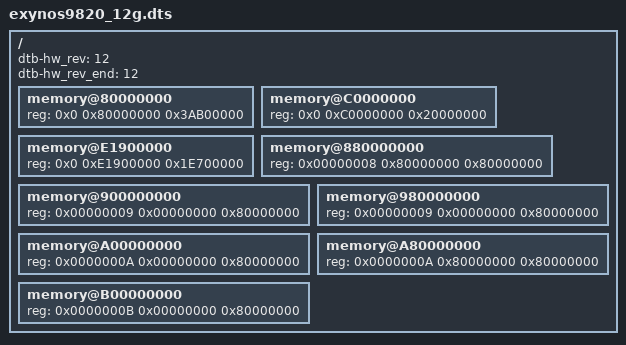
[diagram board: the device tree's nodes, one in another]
/*
 * SAMSUNG EXYNOS9820 SoC device tree source
 *
 * Copyright (c) 2018 Samsung Electronics Co., Ltd.
 *             http://www.samsung.com
 *
 * SAMSUNG EXYNOS9820 SoC device nodes are listed in this file.
 * EXYNOS based board files can include this file and provide
 * values for board specfic bindings.
 *
 * This program is free software; you can redistribute it and/or modify
 * it under the terms of the GNU General Public License version 2 as
 * published by the Free Software Foundation.
 */

/dts-v1/;
#include "exynos9820.dts"
#include "../../../../../include/generated/autoconf.h"

/ {
	dtb-hw_rev = <12>;
    	dtb-hw_rev_end = <12>;

	memory@80000000 {
		device_type = "memory";
		reg = <0x0 0x80000000 0x3AB00000>;
	};

	memory@C0000000 {
		device_type = "memory";
		reg = <0x0 0xC0000000 0x20000000>;
	};

	memory@E1900000 {
		device_type = "memory";
		reg = <0x0 0xE1900000 0x1E700000>; 
	};

	memory@880000000 {
		device_type = "memory";
		reg = <0x00000008 0x80000000 0x80000000>;
	};

	memory@900000000 {
		device_type = "memory";
		reg = <0x00000009 0x00000000 0x80000000>;
	};
	
	memory@980000000 {
		device_type = "memory";
		reg = <0x00000009 0x00000000 0x80000000>;
	};
	
	memory@A00000000 {
		device_type = "memory";
		reg = <0x0000000A 0x00000000 0x80000000>;
	};
	
	memory@A80000000 {
		device_type = "memory";
		reg = <0x0000000A 0x80000000 0x80000000>;
	};
	
	memory@B00000000 {
		device_type = "memory";
		reg = <0x0000000B 0x00000000 0x80000000>;
	};
};
